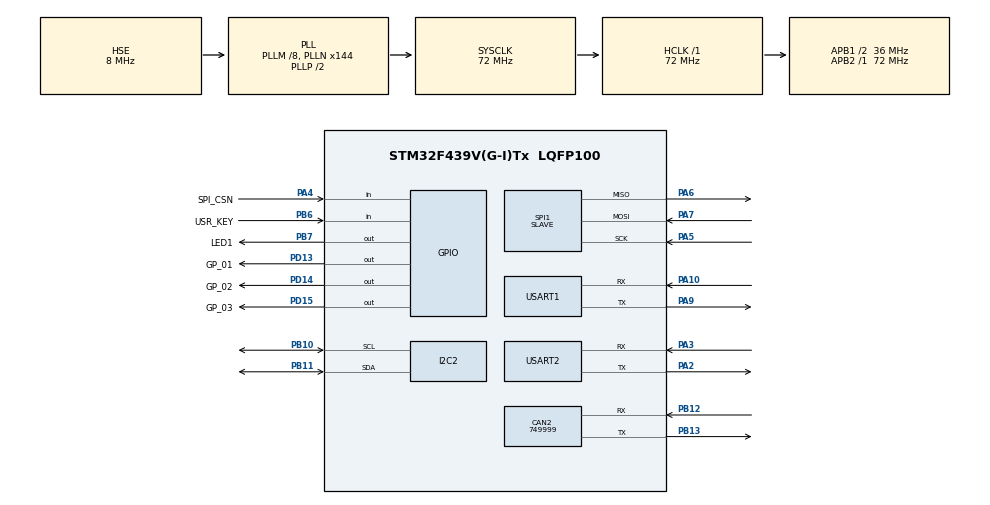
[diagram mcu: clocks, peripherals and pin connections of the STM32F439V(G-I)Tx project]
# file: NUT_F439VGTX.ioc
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CAN2.BS1=CAN_BS1_1TQ
CAN2.BS2=CAN_BS2_1TQ
CAN2.CalculateBaudRate=749999
CAN2.CalculateTimeBit=1333
CAN2.CalculateTimeQuantum=444.44444444444446
CRYP.Algorithm=CRYP_AES_ECB
CRYP.DataType=CRYP_DATATYPE_8B
CRYP.DataWidthUnit=CRYP_DATAWIDTHUNIT_BYTE
I2C2.OwnAddress=0x2A
Mcu.Family=STM32F4
Mcu.Name=STM32F439V(G-I)Tx
Mcu.Package=LQFP100
NVIC.I2C2_ER_IRQn=true\:0\:0\:false\:false\:true\:true\:true\:true
NVIC.I2C2_EV_IRQn=true\:0\:0\:false\:false\:true\:true\:true\:true
NVIC.PriorityGroup=NVIC_PRIORITYGROUP_4
NVIC.SPI1_IRQn=true\:0\:0\:false\:false\:true\:true\:true\:true
NVIC.USART1_IRQn=true\:0\:0\:false\:false\:true\:true\:true\:true
PA10.Mode=Asynchronous
PA10.Signal=USART1_RX
PA13.Mode=Serial_Wire
PA13.Signal=SYS_JTMS-SWDIO
PA14.Mode=Serial_Wire
PA14.Signal=SYS_JTCK-SWCLK
PA15.Signal=SYS_JTDI
PA2.Mode=Asynchronous
PA2.Signal=USART2_TX
PA3.Mode=Asynchronous
PA3.Signal=USART2_RX
PA4.GPIO_Label=SPI_CSN
PA4.GPIO_PuPd=GPIO_PULLUP
PA4.Signal=GPIO_Input
PA5.Mode=Full_Duplex_Slave
PA5.Signal=SPI1_SCK
PA6.Mode=Full_Duplex_Slave
PA6.Signal=SPI1_MISO
PA7.Mode=Full_Duplex_Slave
PA7.Signal=SPI1_MOSI
PA9.Mode=Asynchronous
PA9.Signal=USART1_TX
PB10.Mode=I2C
PB10.Signal=I2C2_SCL
PB11.Mode=I2C
PB11.Signal=I2C2_SDA
PB12.Mode=CAN_Activate
PB12.Signal=CAN2_RX
PB13.Mode=CAN_Activate
PB13.Signal=CAN2_TX
PB3.Signal=SYS_JTDO-SWO
PB4.Signal=SYS_JTRST
PB6.GPIO_Label=USR_KEY
PB6.Signal=GPIO_Input
PB7.GPIO_Label=LED1
PB7.Signal=GPIO_Output
PD13.GPIO_Label=GP_01
PD13.Signal=GPIO_Output
PD14.GPIO_Label=GP_02
PD14.Signal=GPIO_Output
PD15.GPIO_Label=GP_03
PD15.Signal=GPIO_Output
PH0/OSC_IN.Mode=HSE-External-Clock-Source
PH0/OSC_IN.Signal=RCC_OSC_IN
PH1/OSC_OUT.Mode=HSE-External-Clock-Source
PH1/OSC_OUT.Signal=RCC_OSC_OUT
ProjectManager.HeapSize=0x200
ProjectManager.StackSize=0x400
ProjectManager.TargetToolchain=STM32CubeIDE
RCC.48MHZClocksFreq_Value=36000000
RCC.AHBFreq_Value=72000000
RCC.APB1CLKDivider=RCC_HCLK_DIV2
RCC.APB1Freq_Value=36000000
RCC.APB1TimFreq_Value=72000000
RCC.APB2Freq_Value=72000000
RCC.APB2TimFreq_Value=72000000
RCC.CortexFreq_Value=72000000
RCC.DATA_CACHE_ENABLE=0
RCC.HCLKFreq_Value=72000000
RCC.HSE_VALUE=8000000
RCC.HSI_VALUE=16000000
RCC.INSTRUCTION_CACHE_ENABLE=0
RCC.LSE_VALUE=32768
RCC.PLLM=8
RCC.PLLN=144
RCC.PLLSourceVirtual=RCC_PLLSOURCE_HSE
RCC.PREFETCH_ENABLE=0
RCC.SYSCLKFreq_VALUE=72000000
RCC.SYSCLKSource=RCC_SYSCLKSOURCE_PLLCLK
RCC.VCOOutputFreq_Value=144000000
SPI1.Direction=SPI_DIRECTION_2LINES
SPI1.Mode=SPI_MODE_SLAVE
SPI1.VirtualType=VM_SLAVE
USART1.OverSampling=UART_OVERSAMPLING_16
USART1.VirtualMode=VM_ASYNC
USART2.VirtualMode=VM_ASYNC
VP_CRYP_VS_CRYP.Mode=CRYP_Activate
board=custom

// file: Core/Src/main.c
/* USER CODE BEGIN Header */
/**
 ******************************************************************************
 * @file           : main.c
 * @brief          : Main program body
 ******************************************************************************
 * @attention
 *
 * Copyright (c) 2025 STMicroelectronics.
 * All rights reserved.
 *
 * This software is licensed under terms that can be found in the LICENSE file
 * in the root directory of this software component.
 * If no LICENSE file comes with this software, it is provided AS-IS.
 *
 ******************************************************************************
 */
/* USER CODE END Header */
#include "main.h"

/* USER CODE BEGIN Includes */
#include "NutsLib.h"
/* USER CODE END Includes */

CAN_HandleTypeDef hcan2;

CRYP_HandleTypeDef hcryp;
__ALIGN_BEGIN static const uint32_t pKeyCRYP[4] __ALIGN_END = {
                            0x00000000,0x00000000,0x00000000,0x00000000};

I2C_HandleTypeDef hi2c2;

SPI_HandleTypeDef hspi1;

UART_HandleTypeDef huart1;
UART_HandleTypeDef huart2;

void SystemClock_Config(void);
static void MX_GPIO_Init(void);
static void MX_CAN2_Init(void);
static void MX_I2C2_Init(void);
static void MX_SPI1_Init(void);
static void MX_USART1_UART_Init(void);
static void MX_USART2_UART_Init(void);
static void MX_CRYP_Init(void);

int main(void)
{

  /* MCU Configuration--------------------------------------------------------*/

  /* Reset of all peripherals, Initializes the Flash interface and the Systick. */
  HAL_Init();

  /* Configure the system clock */
  SystemClock_Config();

  /* Initialize all configured peripherals */
  MX_GPIO_Init();
  MX_CAN2_Init();
  MX_I2C2_Init();
  MX_SPI1_Init();
  MX_USART1_UART_Init();
  MX_USART2_UART_Init();
  MX_CRYP_Init();
  /* USER CODE BEGIN 2 */
	Nut_Init();
  /* USER CODE END 2 */

  /* Infinite loop */
  /* USER CODE BEGIN WHILE */
	while (1) {
		Nut_Loop();
    /* USER CODE END WHILE */

	}
}

void SystemClock_Config(void)
{
  RCC_OscInitTypeDef RCC_OscInitStruct = {0};
  RCC_ClkInitTypeDef RCC_ClkInitStruct = {0};

  /** Configure the main internal regulator output voltage
  */
  __HAL_RCC_PWR_CLK_ENABLE();
  __HAL_PWR_VOLTAGESCALING_CONFIG(PWR_REGULATOR_VOLTAGE_SCALE3);

  /** Initializes the RCC Oscillators according to the specified parameters
  * in the RCC_OscInitTypeDef structure.
  */
  RCC_OscInitStruct.OscillatorType = RCC_OSCILLATORTYPE_HSE;
  RCC_OscInitStruct.HSEState = RCC_HSE_BYPASS;
  RCC_OscInitStruct.PLL.PLLState = RCC_PLL_ON;
  RCC_OscInitStruct.PLL.PLLSource = RCC_PLLSOURCE_HSE;
  RCC_OscInitStruct.PLL.PLLM = 8;
  RCC_OscInitStruct.PLL.PLLN = 144;
  RCC_OscInitStruct.PLL.PLLP = RCC_PLLP_DIV2;
  RCC_OscInitStruct.PLL.PLLQ = 4;
  if (HAL_RCC_OscConfig(&RCC_OscInitStruct) != HAL_OK)
  {
    Error_Handler();
  }

  /** Initializes the CPU, AHB and APB buses clocks
  */
  RCC_ClkInitStruct.ClockType = RCC_CLOCKTYPE_HCLK|RCC_CLOCKTYPE_SYSCLK
                              |RCC_CLOCKTYPE_PCLK1|RCC_CLOCKTYPE_PCLK2;
  RCC_ClkInitStruct.SYSCLKSource = RCC_SYSCLKSOURCE_PLLCLK;
  RCC_ClkInitStruct.AHBCLKDivider = RCC_SYSCLK_DIV1;
  RCC_ClkInitStruct.APB1CLKDivider = RCC_HCLK_DIV2;
  RCC_ClkInitStruct.APB2CLKDivider = RCC_HCLK_DIV1;

  if (HAL_RCC_ClockConfig(&RCC_ClkInitStruct, FLASH_LATENCY_2) != HAL_OK)
  {
    Error_Handler();
  }
}

static void MX_CAN2_Init(void)
{

  hcan2.Instance = CAN2;
  hcan2.Init.Prescaler = 16;
  hcan2.Init.Mode = CAN_MODE_NORMAL;
  hcan2.Init.SyncJumpWidth = CAN_SJW_1TQ;
  hcan2.Init.TimeSeg1 = CAN_BS1_1TQ;
  hcan2.Init.TimeSeg2 = CAN_BS2_1TQ;
  hcan2.Init.TimeTriggeredMode = DISABLE;
  hcan2.Init.AutoBusOff = DISABLE;
  hcan2.Init.AutoWakeUp = DISABLE;
  hcan2.Init.AutoRetransmission = DISABLE;
  hcan2.Init.ReceiveFifoLocked = DISABLE;
  hcan2.Init.TransmitFifoPriority = DISABLE;
  if (HAL_CAN_Init(&hcan2) != HAL_OK)
  {
    Error_Handler();
  }

}

static void MX_CRYP_Init(void)
{

  hcryp.Instance = CRYP;
  hcryp.Init.DataType = CRYP_DATATYPE_8B;
  hcryp.Init.KeySize = CRYP_KEYSIZE_128B;
  hcryp.Init.pKey = (uint32_t *)pKeyCRYP;
  hcryp.Init.Algorithm = CRYP_AES_ECB;
  hcryp.Init.DataWidthUnit = CRYP_DATAWIDTHUNIT_BYTE;
  if (HAL_CRYP_Init(&hcryp) != HAL_OK)
  {
    Error_Handler();
  }

}

static void MX_I2C2_Init(void)
{

  hi2c2.Instance = I2C2;
  hi2c2.Init.ClockSpeed = 100000;
  hi2c2.Init.DutyCycle = I2C_DUTYCYCLE_2;
  hi2c2.Init.OwnAddress1 = 84;
  hi2c2.Init.AddressingMode = I2C_ADDRESSINGMODE_7BIT;
  hi2c2.Init.DualAddressMode = I2C_DUALADDRESS_DISABLE;
  hi2c2.Init.OwnAddress2 = 0;
  hi2c2.Init.GeneralCallMode = I2C_GENERALCALL_DISABLE;
  hi2c2.Init.NoStretchMode = I2C_NOSTRETCH_DISABLE;
  if (HAL_I2C_Init(&hi2c2) != HAL_OK)
  {
    Error_Handler();
  }

  /** Configure Analogue filter
  */
  if (HAL_I2CEx_ConfigAnalogFilter(&hi2c2, I2C_ANALOGFILTER_ENABLE) != HAL_OK)
  {
    Error_Handler();
  }

  /** Configure Digital filter
  */
  if (HAL_I2CEx_ConfigDigitalFilter(&hi2c2, 0) != HAL_OK)
  {
    Error_Handler();
  }

}

static void MX_SPI1_Init(void)
{

  /* SPI1 parameter configuration*/
  hspi1.Instance = SPI1;
  hspi1.Init.Mode = SPI_MODE_SLAVE;
  hspi1.Init.Direction = SPI_DIRECTION_2LINES;
  hspi1.Init.DataSize = SPI_DATASIZE_8BIT;
  hspi1.Init.CLKPolarity = SPI_POLARITY_LOW;
  hspi1.Init.CLKPhase = SPI_PHASE_1EDGE;
  hspi1.Init.NSS = SPI_NSS_SOFT;
  hspi1.Init.FirstBit = SPI_FIRSTBIT_MSB;
  hspi1.Init.TIMode = SPI_TIMODE_DISABLE;
  hspi1.Init.CRCCalculation = SPI_CRCCALCULATION_DISABLE;
  hspi1.Init.CRCPolynomial = 10;
  if (HAL_SPI_Init(&hspi1) != HAL_OK)
  {
    Error_Handler();
  }

}

static void MX_USART1_UART_Init(void)
{

  huart1.Instance = USART1;
  huart1.Init.BaudRate = 115200;
  huart1.Init.WordLength = UART_WORDLENGTH_8B;
  huart1.Init.StopBits = UART_STOPBITS_1;
  huart1.Init.Parity = UART_PARITY_NONE;
  huart1.Init.Mode = UART_MODE_TX_RX;
  huart1.Init.HwFlowCtl = UART_HWCONTROL_NONE;
  huart1.Init.OverSampling = UART_OVERSAMPLING_16;
  if (HAL_UART_Init(&huart1) != HAL_OK)
  {
    Error_Handler();
  }

}

static void MX_USART2_UART_Init(void)
{

  huart2.Instance = USART2;
  huart2.Init.BaudRate = 115200;
  huart2.Init.WordLength = UART_WORDLENGTH_8B;
  huart2.Init.StopBits = UART_STOPBITS_1;
  huart2.Init.Parity = UART_PARITY_NONE;
  huart2.Init.Mode = UART_MODE_TX_RX;
  huart2.Init.HwFlowCtl = UART_HWCONTROL_NONE;
  huart2.Init.OverSampling = UART_OVERSAMPLING_16;
  if (HAL_UART_Init(&huart2) != HAL_OK)
  {
    Error_Handler();
  }

}

static void MX_GPIO_Init(void)
{
  GPIO_InitTypeDef GPIO_InitStruct = {0};

  /* GPIO Ports Clock Enable */
  __HAL_RCC_GPIOH_CLK_ENABLE();
  __HAL_RCC_GPIOA_CLK_ENABLE();
  __HAL_RCC_GPIOB_CLK_ENABLE();
  __HAL_RCC_GPIOD_CLK_ENABLE();

  /*Configure GPIO pin Output Level */
  HAL_GPIO_WritePin(GPIOD, GP_01_Pin|GP_02_Pin|GP_03_Pin, GPIO_PIN_RESET);

  /*Configure GPIO pin Output Level */
  HAL_GPIO_WritePin(LED1_GPIO_Port, LED1_Pin, GPIO_PIN_RESET);

  /*Configure GPIO pin : SPI_CSN_Pin */
  GPIO_InitStruct.Pin = SPI_CSN_Pin;
  GPIO_InitStruct.Mode = GPIO_MODE_INPUT;
  GPIO_InitStruct.Pull = GPIO_PULLUP;
  HAL_GPIO_Init(SPI_CSN_GPIO_Port, &GPIO_InitStruct);

  /*Configure GPIO pins : GP_01_Pin GP_02_Pin GP_03_Pin */
  GPIO_InitStruct.Pin = GP_01_Pin|GP_02_Pin|GP_03_Pin;
  GPIO_InitStruct.Mode = GPIO_MODE_OUTPUT_PP;
  GPIO_InitStruct.Pull = GPIO_NOPULL;
  GPIO_InitStruct.Speed = GPIO_SPEED_FREQ_LOW;
  HAL_GPIO_Init(GPIOD, &GPIO_InitStruct);

  /*Configure GPIO pin : USR_KEY_Pin */
  GPIO_InitStruct.Pin = USR_KEY_Pin;
  GPIO_InitStruct.Mode = GPIO_MODE_INPUT;
  GPIO_InitStruct.Pull = GPIO_NOPULL;
  HAL_GPIO_Init(USR_KEY_GPIO_Port, &GPIO_InitStruct);

  /*Configure GPIO pin : LED1_Pin */
  GPIO_InitStruct.Pin = LED1_Pin;
  GPIO_InitStruct.Mode = GPIO_MODE_OUTPUT_PP;
  GPIO_InitStruct.Pull = GPIO_NOPULL;
  GPIO_InitStruct.Speed = GPIO_SPEED_FREQ_LOW;
  HAL_GPIO_Init(LED1_GPIO_Port, &GPIO_InitStruct);

}

void Error_Handler(void)
{
	__disable_irq();
	while (1) {
	}
}
